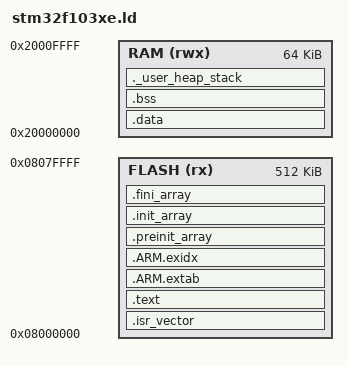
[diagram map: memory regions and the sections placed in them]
/* STM32F103xE 512KB Flash, 64KB RAM */

/* Memory layout must match Keil project: IROM 0x08000000 0x00080000, IRAM 0x20000000 0x00010000 */

ENTRY(Reset_Handler)

_estack = 0x20000000 + 0x10000; /* end of RAM */

MEMORY
{
  FLASH (rx)  : ORIGIN = 0x08000000, LENGTH = 512K
  RAM   (rwx) : ORIGIN = 0x20000000, LENGTH = 64K
}

SECTIONS
{
  .isr_vector :
  {
    KEEP(*(.isr_vector))
  } > FLASH

  .text :
  {
    *(.text*)
    *(.rodata*)
    *(.glue_7)
    *(.glue_7t)
    *(.eh_frame)
  } > FLASH

  .ARM.extab : { *(.ARM.extab* .gnu.linkonce.armextab.*) } > FLASH
  .ARM.exidx : { __exidx_start = .; *(.ARM.exidx*) __exidx_end = .; } > FLASH

  .preinit_array :
  {
    PROVIDE_HIDDEN (__preinit_array_start = .);
    KEEP (*(.preinit_array*))
    PROVIDE_HIDDEN (__preinit_array_end = .);
  } > FLASH

  .init_array :
  {
    PROVIDE_HIDDEN (__init_array_start = .);
    KEEP (*(SORT(.init_array.*)))
    KEEP (*(.init_array*))
    PROVIDE_HIDDEN (__init_array_end = .);
  } > FLASH

  .fini_array :
  {
    PROVIDE_HIDDEN (__fini_array_start = .);
    KEEP (*(.fini_array*))
    KEEP (*(SORT(.fini_array.*)))
    PROVIDE_HIDDEN (__fini_array_end = .);
  } > FLASH

  . = ALIGN(4);
  _etext = .;
  _sidata = _etext; /* start of initialized data in FLASH */

  .data : AT ( _etext )
  {
    _sdata = .;
    *(.data*)
    . = ALIGN(4);
    _edata = .;
  } > RAM

  .bss :
  {
    _sbss = .;
    *(.bss*)
    *(COMMON)
    . = ALIGN(4);
    _ebss = .;
  } > RAM

  /* Heap and stack region (optional, Microlib/newlib nano uses _sbrk) */
  ._user_heap_stack :
  {
    . = ALIGN(8);
    PROVIDE(end = .);
    PROVIDE(_end = .);
  } > RAM
}
